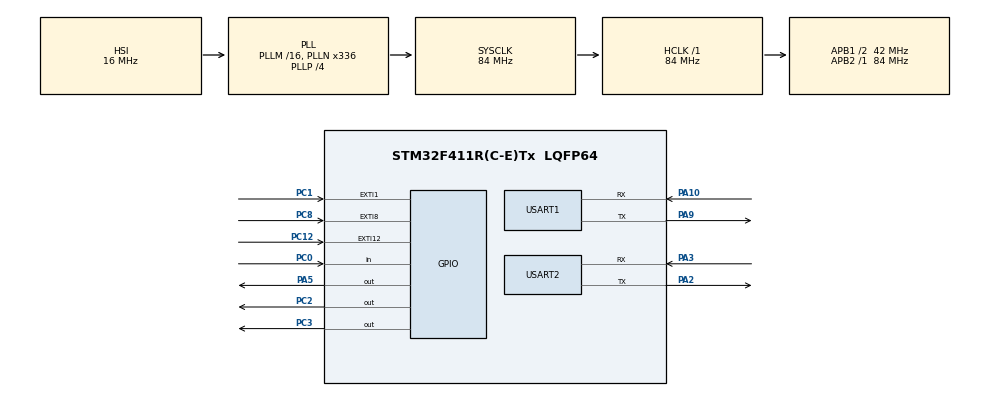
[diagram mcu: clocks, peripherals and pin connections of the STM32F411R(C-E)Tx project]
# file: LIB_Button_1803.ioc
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Mcu.Family=STM32F4
VP_TIM5_VS_ClockSourceINT.Mode=Internal
RCC.CortexFreq_Value=84000000
PA10.Mode=Asynchronous
PC12.Signal=GPXTI12
PH1\ -\ OSC_OUT.Mode=HSE-External-Oscillator
PC8.Signal=GPXTI8
PC2.Signal=GPIO_Output
PC0.Signal=GPIO_Input
RCC.APB1CLKDivider=RCC_HCLK_DIV2
NVIC.USART2_IRQn=true\:0\:0\:false\:false\:true\:true\:true
RCC.SYSCLKSource=RCC_SYSCLKSOURCE_PLLCLK
ProjectManager.StackSize=0x400
PA3.Mode=Asynchronous
NVIC.EXTI1_IRQn=true\:0\:0\:false\:false\:true\:true\:true
PA9.Mode=Asynchronous
PH0\ -\ OSC_IN.Mode=HSE-External-Oscillator
PH0\ -\ OSC_IN.Signal=RCC_OSC_IN
ProjectManager.TargetToolchain=STM32CubeIDE
NVIC.TIM5_IRQn=true\:0\:0\:false\:false\:true\:true\:true
RCC.HCLKFreq_Value=84000000
RCC.APB2TimFreq_Value=84000000
PA9.Signal=USART1_TX
PC3.Signal=GPIO_Output
RCC.LSE_VALUE=32768
RCC.AHBFreq_Value=84000000
NVIC.EXTI15_10_IRQn=true\:0\:0\:false\:false\:true\:true\:true
PA5.Signal=GPIO_Output
RCC.HSE_VALUE=25000000
PH1\ -\ OSC_OUT.Signal=RCC_OSC_OUT
board=custom
RCC.VCOOutputFreq_Value=336000000
NVIC.TIM3_IRQn=true\:0\:0\:false\:false\:true\:true\:true
RCC.APB2Freq_Value=84000000
Mcu.Name=STM32F411R(C-E)Tx
PA2.Signal=USART2_TX
RCC.48MHZClocksFreq_Value=84000000
RCC.SYSCLKFreq_VALUE=84000000
Mcu.Package=LQFP64
NVIC.TimeBase=TIM4_IRQn
USART2.VirtualMode=VM_ASYNC
USART1.VirtualMode=VM_ASYNC
NVIC.EXTI9_5_IRQn=true\:0\:0\:false\:false\:true\:true\:true
NVIC.TimeBaseIP=TIM4
PA10.Signal=USART1_RX
ProjectManager.HeapSize=0x200
VP_SYS_VS_tim4.Mode=TIM4
RCC.HSI_VALUE=16000000
RCC.PLLP=RCC_PLLP_DIV4
NVIC.PriorityGroup=NVIC_PRIORITYGROUP_4
PC8.GPIO_ModeDefaultEXTI=GPIO_MODE_IT_RISING_FALLING
RCC.PLLN=336
RCC.APB1TimFreq_Value=84000000
PA2.Mode=Asynchronous
TIM5.Period=50
NVIC.USART1_IRQn=true\:0\:0\:false\:false\:true\:true\:true
NVIC.TIM4_IRQn=true\:0\:0\:false\:false\:true\:false\:true
RCC.APB1Freq_Value=42000000
VP_TIM3_VS_ClockSourceINT.Mode=Internal
PC1.Signal=GPXTI1
PA3.Signal=USART2_RX

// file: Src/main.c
/* USER CODE BEGIN Header */
/**
  ******************************************************************************
  * @file           : main.c
  * @brief          : Main program body
  ******************************************************************************
  * @attention
  *
  * <h2><center>&copy; Copyright (c) 2020 STMicroelectronics.
  * All rights reserved.</center></h2>
  *
  * This software component is licensed by ST under BSD 3-Clause license,
  * the "License"; You may not use this file except in compliance with the
  * License. You may obtain a copy of the License at:
  *                        opensource.org/licenses/BSD-3-Clause
  *
  ******************************************************************************
  */
/* USER CODE END Header */

#include "main.h"

uint32_t now;
uint32_t future;
int long_press = 0;
int state = 1;
int count = 0;
char buffer[50], buffer1[50];
int Switch_button = 0, Speed_button = 0, flagPBT, flagSBT ;

TIM_HandleTypeDef htim3;
TIM_HandleTypeDef htim5;

UART_HandleTypeDef huart1;
UART_HandleTypeDef huart2;

void SystemClock_Config(void);
static void MX_GPIO_Init(void);
static void MX_TIM3_Init(void);
static void MX_TIM5_Init(void);
static void MX_USART1_UART_Init(void);
static void MX_USART2_UART_Init(void);

int main(void)
{

  /* MCU Configuration--------------------------------------------------------*/

  /* Reset of all peripherals, Initializes the Flash interface and the Systick. */
  HAL_Init();

  /* Configure the system clock */
  SystemClock_Config();

  /* Initialize all configured peripherals */
  MX_GPIO_Init();
  MX_TIM3_Init();
  MX_TIM5_Init();
  MX_USART1_UART_Init();
  MX_USART2_UART_Init();

  /* Infinite loop */
  /* USER CODE BEGIN WHILE */
  while (1)
     {
 	  sprintf(buffer1,"Gia tri output %d\r\n",count);

 	  HAL_UART_Transmit(&huart2, (uint8_t*)&buffer1, sizeof(buffer1), 100);
       /* USER CODE END WHILE */
   	  if (!HAL_GPIO_ReadPin(GPIOC,GPIO_PIN_1)){
   		//  HAL_GPIO_WritePin(GPIOA,GPIO_PIN_5, GPIO_PIN_SET);
   		  //HAL_GPIO_WritePin(GPIOC,GPIO_PIN_3, GPIO_PIN_RESET);
   		  future = HAL_GetTick();
   		  HAL_GPIO_TogglePin(GPIOC,GPIO_PIN_3);
   		  HAL_Delay(2000);
   	  }
   	  else {
   		  now = HAL_GetTick();
   		  if (now > future + 6000){
   			  HAL_GPIO_TogglePin(GPIOC,GPIO_PIN_3);
   			  HAL_Delay(100);
   		  }

   		  else {
   			HAL_GPIO_TogglePin(GPIOC,GPIO_PIN_3);
   			HAL_Delay(2000);
   		  }

   		  //HAL_GPIO_WritePin(GPIOA,GPIO_PIN_5, GPIO_PIN_RESET);
   		  //HAL_GPIO_WritePin(GPIOC,GPIO_PIN_3, GPIO_PIN_SET);
   	  }

   	 /* if (long_press == 0){
   		  HAL_GPIO_WritePin(GPIOA,GPIO_PIN_5, GPIO_PIN_SET);
   		  future = HAL_GetTick() + 6000;
   	  }
   	  else {
   		  HAL_GPIO_WritePin(GPIOA,GPIO_PIN_5, GPIO_PIN_RESET);
   		  //future = HAL_GetTick() + 6000;
   	  }*/
   	  HAL_Delay(1000);
   	  HAL_GPIO_WritePin(GPIOA,GPIO_PIN_5, GPIO_PIN_RESET);

     }
   }

   void HAL_GPIO_EXTI_Callback(uint16_t GPIO_Pin)
   {
   	if(GPIO_Pin==GPIO_PIN_1 && state == 1)
   		{

   			if (now > future){
   				long_press = 0;
   			}
   			else{
   				long_press = 1;
   			}

   			HAL_GPIO_WritePin(GPIOA,GPIO_PIN_5, GPIO_PIN_SET);

   			state = 0;
   			HAL_TIM_Base_Start_IT(&htim5);
   			//HAL_Delay(1000);
   		}

   }

void SystemClock_Config(void)
{
  RCC_OscInitTypeDef RCC_OscInitStruct = {0};
  RCC_ClkInitTypeDef RCC_ClkInitStruct = {0};

  /** Configure the main internal regulator output voltage
  */
  __HAL_RCC_PWR_CLK_ENABLE();
  __HAL_PWR_VOLTAGESCALING_CONFIG(PWR_REGULATOR_VOLTAGE_SCALE1);
  /** Initializes the CPU, AHB and APB busses clocks
  */
  RCC_OscInitStruct.OscillatorType = RCC_OSCILLATORTYPE_HSI;
  RCC_OscInitStruct.HSIState = RCC_HSI_ON;
  RCC_OscInitStruct.HSICalibrationValue = RCC_HSICALIBRATION_DEFAULT;
  RCC_OscInitStruct.PLL.PLLState = RCC_PLL_ON;
  RCC_OscInitStruct.PLL.PLLSource = RCC_PLLSOURCE_HSI;
  RCC_OscInitStruct.PLL.PLLM = 16;
  RCC_OscInitStruct.PLL.PLLN = 336;
  RCC_OscInitStruct.PLL.PLLP = RCC_PLLP_DIV4;
  RCC_OscInitStruct.PLL.PLLQ = 4;
  if (HAL_RCC_OscConfig(&RCC_OscInitStruct) != HAL_OK)
  {
    Error_Handler();
  }
  /** Initializes the CPU, AHB and APB busses clocks
  */
  RCC_ClkInitStruct.ClockType = RCC_CLOCKTYPE_HCLK|RCC_CLOCKTYPE_SYSCLK
                              |RCC_CLOCKTYPE_PCLK1|RCC_CLOCKTYPE_PCLK2;
  RCC_ClkInitStruct.SYSCLKSource = RCC_SYSCLKSOURCE_PLLCLK;
  RCC_ClkInitStruct.AHBCLKDivider = RCC_SYSCLK_DIV1;
  RCC_ClkInitStruct.APB1CLKDivider = RCC_HCLK_DIV2;
  RCC_ClkInitStruct.APB2CLKDivider = RCC_HCLK_DIV1;

  if (HAL_RCC_ClockConfig(&RCC_ClkInitStruct, FLASH_LATENCY_2) != HAL_OK)
  {
    Error_Handler();
  }
}

static void MX_TIM3_Init(void)
{

  TIM_ClockConfigTypeDef sClockSourceConfig = {0};
  TIM_MasterConfigTypeDef sMasterConfig = {0};

  htim3.Instance = TIM3;
  htim3.Init.Prescaler = 0;
  htim3.Init.CounterMode = TIM_COUNTERMODE_UP;
  htim3.Init.Period = 0;
  htim3.Init.ClockDivision = TIM_CLOCKDIVISION_DIV1;
  htim3.Init.AutoReloadPreload = TIM_AUTORELOAD_PRELOAD_DISABLE;
  if (HAL_TIM_Base_Init(&htim3) != HAL_OK)
  {
    Error_Handler();
  }
  sClockSourceConfig.ClockSource = TIM_CLOCKSOURCE_INTERNAL;
  if (HAL_TIM_ConfigClockSource(&htim3, &sClockSourceConfig) != HAL_OK)
  {
    Error_Handler();
  }
  sMasterConfig.MasterOutputTrigger = TIM_TRGO_RESET;
  sMasterConfig.MasterSlaveMode = TIM_MASTERSLAVEMODE_DISABLE;
  if (HAL_TIMEx_MasterConfigSynchronization(&htim3, &sMasterConfig) != HAL_OK)
  {
    Error_Handler();
  }

}

static void MX_TIM5_Init(void)
{

  TIM_ClockConfigTypeDef sClockSourceConfig = {0};
  TIM_MasterConfigTypeDef sMasterConfig = {0};

  htim5.Instance = TIM5;
  htim5.Init.Prescaler = 84000;
  htim5.Init.CounterMode = TIM_COUNTERMODE_UP;
  htim5.Init.Period = 50;
  htim5.Init.ClockDivision = TIM_CLOCKDIVISION_DIV1;
  htim5.Init.AutoReloadPreload = TIM_AUTORELOAD_PRELOAD_DISABLE;
  if (HAL_TIM_Base_Init(&htim5) != HAL_OK)
  {
    Error_Handler();
  }
  sClockSourceConfig.ClockSource = TIM_CLOCKSOURCE_INTERNAL;
  if (HAL_TIM_ConfigClockSource(&htim5, &sClockSourceConfig) != HAL_OK)
  {
    Error_Handler();
  }
  sMasterConfig.MasterOutputTrigger = TIM_TRGO_RESET;
  sMasterConfig.MasterSlaveMode = TIM_MASTERSLAVEMODE_DISABLE;
  if (HAL_TIMEx_MasterConfigSynchronization(&htim5, &sMasterConfig) != HAL_OK)
  {
    Error_Handler();
  }

}

static void MX_USART1_UART_Init(void)
{

  huart1.Instance = USART1;
  huart1.Init.BaudRate = 115200;
  huart1.Init.WordLength = UART_WORDLENGTH_8B;
  huart1.Init.StopBits = UART_STOPBITS_1;
  huart1.Init.Parity = UART_PARITY_NONE;
  huart1.Init.Mode = UART_MODE_TX_RX;
  huart1.Init.HwFlowCtl = UART_HWCONTROL_NONE;
  huart1.Init.OverSampling = UART_OVERSAMPLING_16;
  if (HAL_UART_Init(&huart1) != HAL_OK)
  {
    Error_Handler();
  }

}

static void MX_USART2_UART_Init(void)
{

  huart2.Instance = USART2;
  huart2.Init.BaudRate = 115200;
  huart2.Init.WordLength = UART_WORDLENGTH_8B;
  huart2.Init.StopBits = UART_STOPBITS_1;
  huart2.Init.Parity = UART_PARITY_NONE;
  huart2.Init.Mode = UART_MODE_TX_RX;
  huart2.Init.HwFlowCtl = UART_HWCONTROL_NONE;
  huart2.Init.OverSampling = UART_OVERSAMPLING_16;
  if (HAL_UART_Init(&huart2) != HAL_OK)
  {
    Error_Handler();
  }

}

static void MX_GPIO_Init(void)
{
  GPIO_InitTypeDef GPIO_InitStruct = {0};

  /* GPIO Ports Clock Enable */
  __HAL_RCC_GPIOH_CLK_ENABLE();
  __HAL_RCC_GPIOC_CLK_ENABLE();
  __HAL_RCC_GPIOA_CLK_ENABLE();

  /*Configure GPIO pin Output Level */
  HAL_GPIO_WritePin(GPIOC, GPIO_PIN_2|GPIO_PIN_3, GPIO_PIN_RESET);

  /*Configure GPIO pin Output Level */
  HAL_GPIO_WritePin(GPIOA, GPIO_PIN_5, GPIO_PIN_RESET);

  /*Configure GPIO pin : PC0 */
  GPIO_InitStruct.Pin = GPIO_PIN_0;
  GPIO_InitStruct.Mode = GPIO_MODE_INPUT;
  GPIO_InitStruct.Pull = GPIO_NOPULL;
  HAL_GPIO_Init(GPIOC, &GPIO_InitStruct);

  /*Configure GPIO pins : PC1 PC12 */
  GPIO_InitStruct.Pin = GPIO_PIN_1|GPIO_PIN_12;
  GPIO_InitStruct.Mode = GPIO_MODE_IT_RISING;
  GPIO_InitStruct.Pull = GPIO_NOPULL;
  HAL_GPIO_Init(GPIOC, &GPIO_InitStruct);

  /*Configure GPIO pins : PC2 PC3 */
  GPIO_InitStruct.Pin = GPIO_PIN_2|GPIO_PIN_3;
  GPIO_InitStruct.Mode = GPIO_MODE_OUTPUT_PP;
  GPIO_InitStruct.Pull = GPIO_NOPULL;
  GPIO_InitStruct.Speed = GPIO_SPEED_FREQ_LOW;
  HAL_GPIO_Init(GPIOC, &GPIO_InitStruct);

  /*Configure GPIO pin : PA5 */
  GPIO_InitStruct.Pin = GPIO_PIN_5;
  GPIO_InitStruct.Mode = GPIO_MODE_OUTPUT_PP;
  GPIO_InitStruct.Pull = GPIO_NOPULL;
  GPIO_InitStruct.Speed = GPIO_SPEED_FREQ_LOW;
  HAL_GPIO_Init(GPIOA, &GPIO_InitStruct);

  /*Configure GPIO pin : PC8 */
  GPIO_InitStruct.Pin = GPIO_PIN_8;
  GPIO_InitStruct.Mode = GPIO_MODE_IT_RISING_FALLING;
  GPIO_InitStruct.Pull = GPIO_NOPULL;
  HAL_GPIO_Init(GPIOC, &GPIO_InitStruct);

  /* EXTI interrupt init*/
  HAL_NVIC_SetPriority(EXTI1_IRQn, 0, 0);
  HAL_NVIC_EnableIRQ(EXTI1_IRQn);

  HAL_NVIC_SetPriority(EXTI9_5_IRQn, 0, 0);
  HAL_NVIC_EnableIRQ(EXTI9_5_IRQn);

  HAL_NVIC_SetPriority(EXTI15_10_IRQn, 0, 0);
  HAL_NVIC_EnableIRQ(EXTI15_10_IRQn);

}

 /**
  * @brief  Period elapsed callback in non blocking mode
  * @note   This function is called  when TIM4 interrupt took place, inside
  * HAL_TIM_IRQHandler(). It makes a direct call to HAL_IncTick() to increment
  * a global variable "uwTick" used as application time base.
  * @param  htim : TIM handle
  * @retval None
  */
void HAL_TIM_PeriodElapsedCallback(TIM_HandleTypeDef *htim)
{
  if (htim->Instance == TIM4) {
    HAL_IncTick();
  }
  /* USER CODE BEGIN Callback 1 */
  if (htim->Instance == TIM5) {
	  if(HAL_GPIO_ReadPin(GPIOC,GPIO_PIN_1) == GPIO_PIN_SET){
		//HAL_GPIO_TogglePin(GPIOD, GPIO_PIN_12);
			count++;
			state = 1;
			sprintf(buffer,"gia tri count %d\r\n",count);
			HAL_UART_Transmit(&huart2, (uint8_t*)&buffer, sizeof(buffer), 100);
			HAL_TIM_Base_Stop_IT(&htim5);
	  }
  }

  /* USER CODE END Callback 1 */
}

void Error_Handler(void)
{
}

/************************ (C) COPYRIGHT STMicroelectronics *****END OF FILE****/
